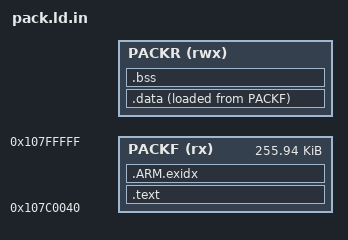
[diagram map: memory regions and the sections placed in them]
/* DoomPack standalone link script TEMPLATE (doom/PACK_DESIGN.md §7).
 * build_pack.sh substitutes:
 *   @RAM_BASE@ - the borrowed overlay pool's address, extracted from the
 *                exact POLYKYBD_DOOM_PACK firmware .elf this pack ships with
 *   @RAM_SIZE@ - the pool size in bytes
 * Flash origin = the DOOMPACK slot's XIP address + the 64 B PlyX header
 * (fw_staging.h FW_DOOMPACK_SLOT_OFF; doom_pack_abi.h doom_pack_hdr_t).
 *
 * Layout mirrors the monolith's .doom_shared model: engine .data + .bss +
 * COMMON at the FRONT of the pool (the "statics"), the game arena after
 * them (__pack_statics_end__ -> hdr.arena_off), the core1 stack at the
 * pool tail — all carved at runtime by the firmware's doom_arena_at.
 */
ENTRY(doom_pack_init)

MEMORY
{
    PACKF (rx)  : ORIGIN = 0x107C0000 + 64, LENGTH = 0x40000 - 64
    PACKR (rwx) : ORIGIN = @RAM_BASE@,      LENGTH = @RAM_SIZE@
}

SECTIONS
{
    .text : ALIGN(4)
    {
        KEEP(*(.text.doom_pack_init))
        *(.text*)
        *(.rodata*)
        . = ALIGN(4);
    } > PACKF

    /* pd_render.cpp is C++ — keep the (empty-in-practice) unwind tables so
       the link never dangles. */
    .ARM.exidx : ALIGN(4)
    {
        __exidx_start = .;
        *(.ARM.exidx*)
        *(.ARM.extab*)
        . = ALIGN(4);
        __exidx_end = .;
    } > PACKF

    .data : ALIGN(4)
    {
        __pack_data_start__ = .;
        *(.data*)
        . = ALIGN(4);
        __pack_data_end__ = .;
    } > PACKR AT > PACKF
    __pack_data_load__ = LOADADDR(.data);

    .bss (NOLOAD) : ALIGN(4)
    {
        __pack_bss_start__ = .;
        *(.bss*)
        *(COMMON)
        . = ALIGN(16);
        __pack_bss_end__ = .;
    } > PACKR
    __pack_statics_end__ = .;

    /DISCARD/ :
    {
        *(.comment)
        *(.debug*)
    }
}
